VERSION ""

NS_ :

BS_:

BU_: BMS Third_Party_Device

BO_ 3221225472 VECTOR__INDEPENDENT_SIG_MSG: 0 Vector__XXX
 SG_ lowest_cell_voltage_too_low_0000 : 17|1@1+ (1,0) [0|1] ""  Third_Party_Device
 SG_ pack_too_hot_fault : 18|1@1+ (1,0) [0|1] ""  Third_Party_Device
 SG_ reduced_high_soc : 23|1@1+ (1,0) [0|0] "" Vector__XXX

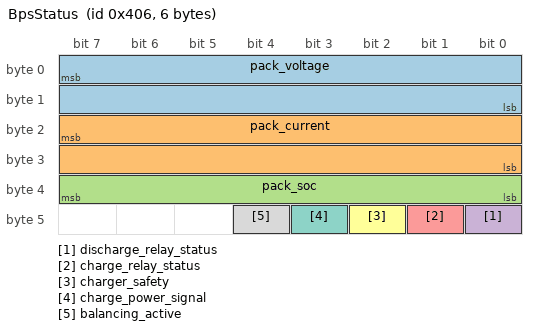
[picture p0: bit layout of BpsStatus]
BO_ 1030 BpsStatus: 6 BMS
 SG_ pack_voltage : 7|16@0+ (0.1,0) [0|0] "Volts"  Third_Party_Device
 SG_ pack_current : 23|16@0- (0.1,0) [0|0] "Amps"  Third_Party_Device
 SG_ pack_soc : 39|8@0+ (0.5,0) [0|0] "Percent"  Third_Party_Device
 SG_ discharge_relay_status : 40|1@1+ (1,0) [0|1] ""  Third_Party_Device
 SG_ charge_relay_status : 41|1@1+ (1,0) [0|1] ""  Third_Party_Device
 SG_ charger_safety : 42|1@1+ (1,0) [0|1] ""  Third_Party_Device
 SG_ charge_power_signal : 43|1@1+ (1,0) [0|1] ""  Third_Party_Device
 SG_ balancing_active : 44|1@1+ (1,0) [0|1] ""  Third_Party_Device

BO_ 938 BpsError: 4 BMS
 SG_ internal_cell_communication_0001 : 0|1@1+ (1,0) [0|1] ""  Third_Party_Device
 SG_ weak_cell_fault : 1|1@1+ (1,0) [0|1] ""  Third_Party_Device
 SG_ low_cell_voltage_fault : 2|1@1+ (1,0) [0|1] ""  Third_Party_Device
 SG_ cell_open_wiring_fault : 3|1@1+ (1,0) [0|1] ""  Third_Party_Device
 SG_ thermistor_fault : 4|1@1+ (1,0) [0|1] ""  Third_Party_Device
 SG_ current_sensor_fault : 5|1@1+ (1,0) [0|1] ""  Third_Party_Device
 SG_ weak_pack_fault : 6|1@1+ (1,0) [0|1] ""  Third_Party_Device
 SG_ can_communication_fault : 7|1@1+ (1,0) [0|1] ""  Third_Party_Device
 SG_ redundant_power_supply_fault : 8|1@1+ (1,0) [0|1] ""  Third_Party_Device
 SG_ high_voltage_isolation_fault : 9|1@1+ (1,0) [0|1] ""  Third_Party_Device
 SG_ charge_enable_relay_fault : 10|1@1+ (1,0) [0|1] ""  Third_Party_Device
 SG_ discharge_enable_relay_fault : 11|1@1+ (1,0) [0|1] ""  Third_Party_Device
 SG_ internal_conversion_fault : 12|1@1+ (1,0) [0|1] ""  Third_Party_Device
 SG_ internal_memory_fault : 13|1@1+ (1,0) [0|1] ""  Third_Party_Device
 SG_ internal_thermistor_fault : 14|1@1+ (1,0) [0|1] ""  Third_Party_Device
 SG_ internal_logic_fault : 15|1@1+ (1,0) [0|1] ""  Third_Party_Device
 SG_ reduced_low_soc : 24|1@1+ (1,0) [0|0] "" Vector__XXX
 SG_ reduced_high_cell_resistance : 25|1@1+ (1,0) [0|0] "" Vector__XXX
 SG_ reduced_high_temp : 26|1@1+ (1,0) [0|0] "" Vector__XXX
 SG_ reduced_low_cell_voltage : 27|1@1+ (1,0) [0|0] "" Vector__XXX
 SG_ reduced_low_pack_voltage : 28|1@1+ (1,0) [0|0] "" Vector__XXX
 SG_ reduced_voltage_failsafe : 30|1@1+ (1,0) [0|0] "" Vector__XXX
 SG_ reduced_comms_failsafe : 31|1@1+ (1,0) [0|0] "" Vector__XXX

CM_ SG_ 3221225472 lowest_cell_voltage_too_low_0000 "fault";
CM_ SG_ 3221225472 pack_too_hot_fault "fault";
CM_ BO_ 1030 "This ID Transmits at 8 ms.";
CM_ BO_ 938 "This ID Transmits at 8 ms.";
CM_ SG_ 938 internal_cell_communication_0001 "fault";
CM_ SG_ 938 low_cell_voltage_fault "fault";
CM_ SG_ 938 thermistor_fault "fault";
CM_ SG_ 938 current_sensor_fault "fault";
CM_ SG_ 938 weak_pack_fault "fault";
CM_ SG_ 938 can_communication_fault "fault";
CM_ SG_ 938 high_voltage_isolation_fault "fault";
CM_ SG_ 938 charge_enable_relay_fault "fault";
CM_ SG_ 938 discharge_enable_relay_fault "fault";
CM_ SG_ 938 internal_conversion_fault "fault";
CM_ SG_ 938 internal_memory_fault "fault";
CM_ SG_ 938 internal_thermistor_fault "fault";
CM_ SG_ 938 internal_logic_fault "fault";
CM_ SG_ 938 reduced_low_soc "fault";
CM_ SG_ 938 reduced_high_cell_resistance "fault";
CM_ SG_ 938 reduced_high_temp "fault";
CM_ SG_ 938 reduced_low_cell_voltage "fault";
CM_ SG_ 938 reduced_low_pack_voltage "faults";
CM_ SG_ 938 reduced_voltage_failsafe "fault";
CM_ SG_ 938 reduced_comms_failsafe "fault";
BA_DEF_ SG_  "SystemSignalLongSymbol" STRING ;
BA_DEF_DEF_  "SystemSignalLongSymbol" "";
BA_ "SystemSignalLongSymbol" SG_ 3221225472 lowest_cell_voltage_too_low_0000 "lowest_cell_voltage_too_low_fault";
BA_ "SystemSignalLongSymbol" SG_ 938 internal_cell_communication_0001 "internal_cell_communication_fault";
